# XMC1100 register map
Vendor: Infineon; File version: 1.3.0 (Reference Manual v1.3)
CPU: CM0 r0p0, little endian, no MPU, no FPU, 2 interrupt priority bits
Registers are 32-bit, read-write, reset 0x0 unless marked. A register's access mark holds for its fields unless they carry their own. Offsets are from the block's base; [hi:lo] are bit positions; {n}, {i} and the like mark numbered series.

## PAU — PAU Unit
Base 0x40000000
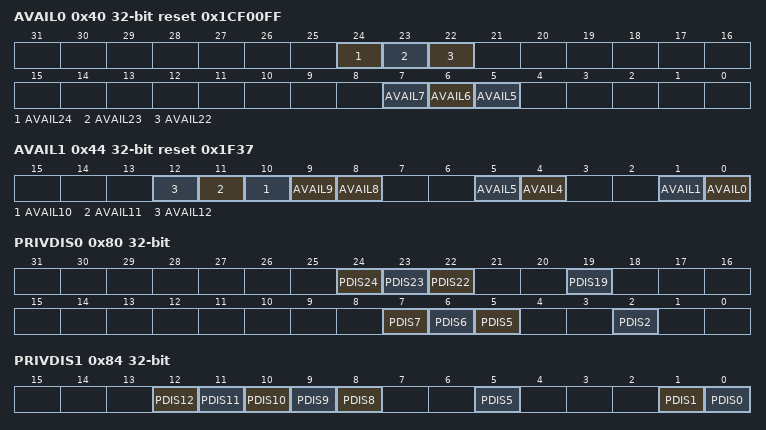
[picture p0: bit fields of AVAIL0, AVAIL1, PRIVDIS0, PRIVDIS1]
0x40 AVAIL0 ro reset 0x1CF00FF — Peripheral Availability Register 0
  [24] AVAIL24 — Port 0 Availability Flag
    0=Port 2 is not available; 1=Port 2 is available
  [23] AVAIL23 — Port 1 Availability Flag
    0=Port 1 is not available; 1=Port 1 is available
  [22] AVAIL22 — Port 0 Availability Flag
    0=Port 0 is not available; 1=Port 0 is available
  [7] AVAIL7 — RAM Block 3 Availability Flag
    0=RAM block 3 is not available; 1=RAM block 3 is available
  [6] AVAIL6 — RAM Block 2 Availability Flag
    0=RAM block 2 is not available; 1=RAM block 2 is available
  [5] AVAIL5 — RAM Block 1 Availability Flag
    0=RAM block 1 is not available; 1=RAM block 1 is available
0x44 AVAIL1 ro reset 0x1F37 — Peripheral Availability Register 1
  [n] AVAIL{n} (n=9..12) — CC{n+31} Availability Flag
    0=CC{n+31} is not available; 1=CC{n+31} is available
  [8] AVAIL8 — SHS0 Availability Flag
    0=SHS0 is not available; 1=SHS0 is available
  [5] AVAIL5 — VADC0 Basic SFRs Availability Flag
    0=VADC0 Basic SFRs are not available; 1=VADC0 Basic SFRs are available
  [4] AVAIL4 — PRNG Availability Flag
    0=PRNG is not available; 1=PRNG is available
  [1] AVAIL1 — USIC0 Channel 1 Availability Flag
    0=USIC0 Channel 1 is not available; 1=USIC0 Channel 1 is available
  [0] AVAIL0 — USIC0 Channel 0 Availability Flag
    0=USIC0 Channel 0 is not available; 1=USIC0 Channel 0 is available
0x48 AVAIL2 access not given — Peripheral Availability Register 2
0x80 PRIVDIS0 — Peripheral Privilege Access Register 0
  [24] PDIS24 — Port 2 Privilege Disable Flag
    0=Port 2 is accessible; 1=Port 2 is not accessible
  [23] PDIS23 — Port 1 Privilege Disable Flag
    0=Port 1 is accessible; 1=Port 1 is not accessible
  [22] PDIS22 — Port 0 Privilege Disable Flag
    0=Port 0 is accessible; 1=Port 0 is not accessible
  [19] PDIS19 — WDT Privilege Disable Flag
    0=WDT is accessible; 1=WDT is not accessible
  [7] PDIS7 — RAM Block 3 Privilege Disable Flag
    0=RAM Block 3 is accessible; 1=RAM Block 3 is not accessible
  [6] PDIS6 — RAM Block 2 Privilege Disable Flag
    0=RAM Block 2 is accessible; 1=RAM Block 2 is not accessible
  [5] PDIS5 — RAM Block 1 Privilege Disable Flag
    0=RAM Block 1 is accessible; 1=RAM Block 1 is not accessible
  [2] PDIS2 — Flash SFRs Privilege Disable Flag
    0=Flash SFRs are accessible; 1=Flash SFRs are not accessible
0x84 PRIVDIS1 — Peripheral Privilege Access Register 1
  [12] PDIS12 — CC43 Privilege Disable Flag
    0=CC43 is accessible; 1=CC43 is not accessible
  [11] PDIS11 — CC42 Privilege Disable Flag
    0=CC42 is accessible; 1=CC42 is not accessible
  [10] PDIS10 — CC41 Privilege Disable Flag
    0=CC41 is accessible; 1=CC41 is not accessible
  [9] PDIS9 — CC40 and CCU40 Kernel SFRs Privilege Disable Flag
    0=CC40 and CCU40 Kernel SFRs are accessible; 1=CC40 and CCU40 Kernel SFRs are not accessible
  [8] PDIS8 — SHS0 Privilege Disable Flag
    0=SHS is accessible; 1=SHS is not accessible
  [5] PDIS5 — VADC0 Basic SFRs Privilege Disable Flag
    0=VADC0 Basic SFRs are accessible; 1=VADC0 Basic SFRs are not accessible
  [1] PDIS1 — USIC0 Channel 1 Privilege Disable Flag
    0=USIC0 Channel 1 is accessible; 1=USIC0 Channel 1 is not accessible
  [0] PDIS0 — USIC0 Channel 0 Privilege Disable Flag
    0=USIC0 Channel 0 is accessible; 1=USIC0 Channel 0 is not accessible
0x400 ROMSIZE ro reset 0xB00
  [13:8] ADDR — ROM Size
0x404 FLSIZE ro reset 0x11000 — Flash Size Register
  [17:12] ADDR — Flash Size
0x410 RAM0SIZE ro reset 0x1000
  [12:8] ADDR — RAM0 Size

## NVM — NVM Unit
Base 0x40050000
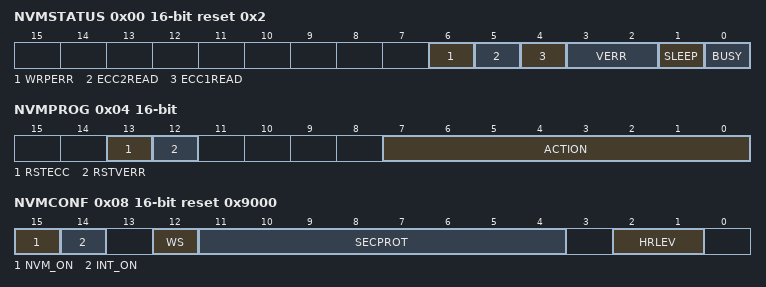
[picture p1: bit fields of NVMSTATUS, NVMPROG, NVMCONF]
0x00 NVMSTATUS 16-bit ro reset 0x2
  [6] WRPERR — Write Protocol Error
    0=No write protocol failure occurred; 1=At least one write protocol failure was detected
  [5] ECC2READ
    0=No ECC two bit failure during memory read operations; 1=At least one ECC two bit failure was detected
  [4] ECC1READ
    0=No ECC single bit failure occurred; 1=At least one ECC single bit failure was detected and corrected
  [3:2] VERR — Verify Error
    0=No fail bit; 1=One fail bit in one data block; 2=Two fail bits in two different data blocks; 3=Two or more fail bits in one data block, or three or more fail bits overall
  [1] SLEEP — Sleep Mode
    0=NVM not in sleep mode, and no sleep or wake up procedure in progress; 1=NVM in sleep mode, or busy due to a sleep or wake up procedure
  [0] BUSY
    0=The NVM is not busy. Memory reads from the cell array and register write accesses are possible.; 1=The NVM is busy. Memory reads and register write accesses are not possible.
0x04 NVMPROG 16-bit — NVM Programming Control Register
  [13] RSTECC — Reset ECC
    0=No action; 1=Reset of .ECCxREAD and NVMSTATUS.WRPERR
  [12] RSTVERR — Reset Verify Error
    0=No action; 1=Reset of .VERR
  [7:0] ACTION — ACTION: [VERIFY, ONE_SHOT, OPTYPE]
    0=Idle state, no action triggered. Writing 0x00 exits current mode.; 81=Start one-shot write operation with automatic verify; 145=Start one-shot write operation without verify; 97=Start continuous write operation with automatic verify of every write; 161=Start continuous write operation without verify; 146=Start one-shot page erase operation; 162=Start continuous page erase operation; 208=Start one-shot verify-only: Written data is compared to array content; 224=Start continuous verify-only: Written data is compared to array content
0x08 NVMCONF 16-bit reset 0x9000 — NVM Configuration Register
  [15] NVM_ON
    0=NVM is switched to or stays in sleep mode; 1=NVM is switched to or stays in normal mode
  [14] INT_ON — Interrupt On
    0=No NVM ready interrupts are generated; 1=NVM ready interrupts are generated
  [12] WS — Number of fixed Wait States
    0=0 fixed wait states; 1=1 fixed wait state
  [11:4] SECPROT — Sector Protection
  [2:1] HRLEV — Hardread Level
    0=Normal read; 1=Hardread written; 2=Hardread erased
0x48 CONFIG1 16-bit reset not defined — Configuration 1 Register
  [11] FIXWS — Wait States Scheme
    0=Const_0 (adaptive wait states.); 1=Const_1 (fixed wait states.)

## Notices in the file
Copyright (C) 2016 Infineon Technologies AG. All rights reserved.
Infineon Technologies AG (Infineon) is supplying this software for use with
Infineon's microcontrollers.  This file can be freely distributed within
development tools that are supporting such microcontrollers.
THIS SOFTWARE IS PROVIDED "AS IS".  NO WARRANTIES, WHETHER EXPRESS, IMPLIED
OR STATUTORY, INCLUDING, BUT NOT LIMITED TO, IMPLIED WARRANTIES OF
MERCHANTABILITY AND FITNESS FOR A PARTICULAR PURPOSE APPLY TO THIS SOFTWARE.
INFINEON SHALL NOT, IN ANY CIRCUMSTANCES, BE LIABLE FOR SPECIAL, INCIDENTAL,
OR CONSEQUENTIAL DAMAGES, FOR ANY REASON WHATSOEVER.
